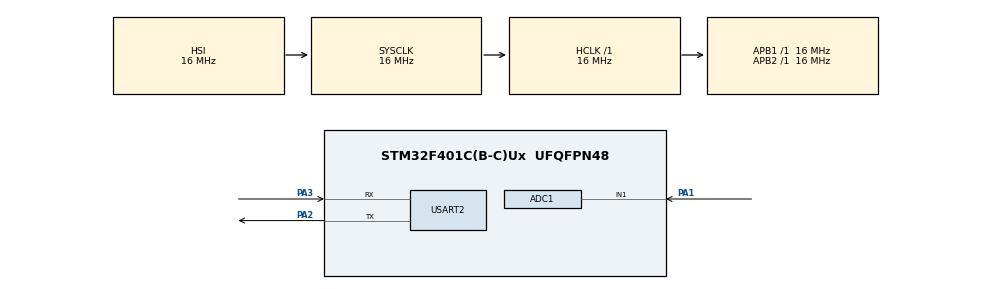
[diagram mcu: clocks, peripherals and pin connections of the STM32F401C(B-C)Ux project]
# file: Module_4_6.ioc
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ADC1.Channel-3\#ChannelRegularConversion=ADC_CHANNEL_1
ADC1.ContinuousConvMode=ENABLE
ADC1.NbrOfConversionFlag=1
ADC1.Rank-3\#ChannelRegularConversion=1
ADC1.SamplingTime-3\#ChannelRegularConversion=ADC_SAMPLETIME_3CYCLES
ADC1.master=1
Dma.ADC1.0.Direction=DMA_PERIPH_TO_MEMORY
Dma.ADC1.0.FIFOMode=DMA_FIFOMODE_DISABLE
Dma.ADC1.0.Instance=DMA2_Stream0
Dma.ADC1.0.MemDataAlignment=DMA_MDATAALIGN_HALFWORD
Dma.ADC1.0.MemInc=DMA_MINC_ENABLE
Dma.ADC1.0.Mode=DMA_CIRCULAR
Dma.ADC1.0.PeriphDataAlignment=DMA_PDATAALIGN_HALFWORD
Dma.ADC1.0.PeriphInc=DMA_PINC_DISABLE
Dma.ADC1.0.Priority=DMA_PRIORITY_LOW
Dma.Request0=ADC1
Dma.Request1=USART2_TX
Dma.USART2_TX.1.Direction=DMA_MEMORY_TO_PERIPH
Dma.USART2_TX.1.FIFOMode=DMA_FIFOMODE_DISABLE
Dma.USART2_TX.1.Instance=DMA1_Stream6
Dma.USART2_TX.1.MemDataAlignment=DMA_MDATAALIGN_BYTE
Dma.USART2_TX.1.MemInc=DMA_MINC_ENABLE
Dma.USART2_TX.1.Mode=DMA_NORMAL
Dma.USART2_TX.1.PeriphDataAlignment=DMA_PDATAALIGN_BYTE
Dma.USART2_TX.1.PeriphInc=DMA_PINC_DISABLE
Dma.USART2_TX.1.Priority=DMA_PRIORITY_LOW
Mcu.Family=STM32F4
Mcu.Name=STM32F401C(B-C)Ux
Mcu.Package=UFQFPN48
NVIC.DMA1_Stream6_IRQn=true\:0\:0\:false\:false\:true\:false\:true\:true
NVIC.DMA2_Stream0_IRQn=true\:0\:0\:false\:false\:true\:false\:true\:true
NVIC.PriorityGroup=NVIC_PRIORITYGROUP_4
NVIC.USART2_IRQn=true\:0\:0\:false\:false\:true\:false\:true\:true
PA1.Signal=ADCx_IN1
PA13.Mode=Serial_Wire
PA13.Signal=SYS_JTMS-SWDIO
PA14.Mode=Serial_Wire
PA14.Signal=SYS_JTCK-SWCLK
PA2.Mode=Asynchronous
PA2.Signal=USART2_TX
PA3.Mode=Asynchronous
PA3.Signal=USART2_RX
ProjectManager.HeapSize=0x200
ProjectManager.StackSize=0x400
ProjectManager.TargetToolchain=STM32CubeIDE
RCC.AHBFreq_Value=16000000
RCC.APB1Freq_Value=16000000
RCC.APB2Freq_Value=16000000
RCC.CortexFreq_Value=16000000
RCC.HSE_VALUE=25000000
RCC.HSI_VALUE=16000000
RCC.LSE_VALUE=32768
RCC.SYSCLKFreq_VALUE=16000000
RCC.VCOOutputFreq_Value=192000000
SH.ADCx_IN1.0=ADC1_IN1,IN1
USART2.VirtualMode=VM_ASYNC
board=custom

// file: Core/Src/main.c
/* USER CODE BEGIN Header */
/**
  ******************************************************************************
  * @file           : main.c
  * @brief          : Main program body
  ******************************************************************************
  * @attention
  *
  * Copyright (c) 2026 STMicroelectronics.
  * All rights reserved.
  *
  * This software is licensed under terms that can be found in the LICENSE file
  * in the root directory of this software component.
  * If no LICENSE file comes with this software, it is provided AS-IS.
  *
  ******************************************************************************
  */
/* USER CODE END Header */
#include "main.h"

/* USER CODE BEGIN Includes */
#include <stdint.h>
#include <string.h>

/* USER CODE END Includes */

ADC_HandleTypeDef hadc1;
DMA_HandleTypeDef hdma_adc1;

UART_HandleTypeDef huart2;
DMA_HandleTypeDef hdma_usart2_tx;

/* USER CODE BEGIN PV */
uint16_t adc_buffer[1000];
/* USER CODE END PV */

void SystemClock_Config(void);
static void MX_GPIO_Init(void);
static void MX_DMA_Init(void);
static void MX_ADC1_Init(void);
static void MX_USART2_UART_Init(void);

/* USER CODE BEGIN 0 */

uint16_t convert_to_mv(uint16_t adc_raw) {
  uint16_t signal_mv = (3300 * adc_raw)/4095 ;
  return signal_mv;
}

void  HAL_ADC_ConvCpltCallback( ADC_HandleTypeDef* hadc) {
   uint16_t min_adc_value=  0;
  uint16_t max_adc_value=  0;
  uint32_t avg_adc_value=  0;
  uint16_t pp_adc_value = 0;
    for (size_t i = 0; i < 1000; i++)
    {
      uint16_t current_value = adc_buffer[i];
      avg_adc_value+=current_value;
      if(i == 0) {
        min_adc_value = current_value;
        max_adc_value = current_value;
        continue;
      }
      if(min_adc_value > current_value) {
        min_adc_value = current_value;
      }
      if(max_adc_value < current_value) {
        max_adc_value = current_value;
      }
    }
    avg_adc_value = avg_adc_value / 1000;
    pp_adc_value = max_adc_value - min_adc_value;

      static char log[80];
      int len = snprintf(log, 80, "Vmax: %d mV; Vmin: %d mV; Vavg: %d mV; Vpp: %d mV\n", convert_to_mv(max_adc_value), convert_to_mv(min_adc_value), convert_to_mv(avg_adc_value), convert_to_mv(pp_adc_value));
      HAL_UART_Transmit_DMA(&huart2, log, len);

}

/* USER CODE END 0 */

int main(void)
{

  /* MCU Configuration--------------------------------------------------------*/

  /* Reset of all peripherals, Initializes the Flash interface and the Systick. */
  HAL_Init();

  /* Configure the system clock */
  SystemClock_Config();

  /* Initialize all configured peripherals */
  MX_GPIO_Init();
  MX_DMA_Init();
  MX_ADC1_Init();
  MX_USART2_UART_Init();
  /* USER CODE BEGIN 2 */
  HAL_ADC_Start_DMA(&hadc1, (uint32_t*)adc_buffer, 1000);
  /* USER CODE END 2 */

  /* Infinite loop */
  while (1)
  {

  }
}

void SystemClock_Config(void)
{
  RCC_OscInitTypeDef RCC_OscInitStruct = {0};
  RCC_ClkInitTypeDef RCC_ClkInitStruct = {0};

  /** Configure the main internal regulator output voltage
  */
  __HAL_RCC_PWR_CLK_ENABLE();
  __HAL_PWR_VOLTAGESCALING_CONFIG(PWR_REGULATOR_VOLTAGE_SCALE2);

  /** Initializes the RCC Oscillators according to the specified parameters
  * in the RCC_OscInitTypeDef structure.
  */
  RCC_OscInitStruct.OscillatorType = RCC_OSCILLATORTYPE_HSI;
  RCC_OscInitStruct.HSIState = RCC_HSI_ON;
  RCC_OscInitStruct.HSICalibrationValue = RCC_HSICALIBRATION_DEFAULT;
  RCC_OscInitStruct.PLL.PLLState = RCC_PLL_NONE;
  if (HAL_RCC_OscConfig(&RCC_OscInitStruct) != HAL_OK)
  {
    Error_Handler();
  }

  /** Initializes the CPU, AHB and APB buses clocks
  */
  RCC_ClkInitStruct.ClockType = RCC_CLOCKTYPE_HCLK|RCC_CLOCKTYPE_SYSCLK
                              |RCC_CLOCKTYPE_PCLK1|RCC_CLOCKTYPE_PCLK2;
  RCC_ClkInitStruct.SYSCLKSource = RCC_SYSCLKSOURCE_HSI;
  RCC_ClkInitStruct.AHBCLKDivider = RCC_SYSCLK_DIV1;
  RCC_ClkInitStruct.APB1CLKDivider = RCC_HCLK_DIV1;
  RCC_ClkInitStruct.APB2CLKDivider = RCC_HCLK_DIV1;

  if (HAL_RCC_ClockConfig(&RCC_ClkInitStruct, FLASH_LATENCY_0) != HAL_OK)
  {
    Error_Handler();
  }
}

static void MX_ADC1_Init(void)
{

  ADC_ChannelConfTypeDef sConfig = {0};

  /** Configure the global features of the ADC (Clock, Resolution, Data Alignment and number of conversion)
  */
  hadc1.Instance = ADC1;
  hadc1.Init.ClockPrescaler = ADC_CLOCK_SYNC_PCLK_DIV2;
  hadc1.Init.Resolution = ADC_RESOLUTION_12B;
  hadc1.Init.ScanConvMode = DISABLE;
  hadc1.Init.ContinuousConvMode = ENABLE;
  hadc1.Init.DiscontinuousConvMode = DISABLE;
  hadc1.Init.ExternalTrigConvEdge = ADC_EXTERNALTRIGCONVEDGE_NONE;
  hadc1.Init.ExternalTrigConv = ADC_SOFTWARE_START;
  hadc1.Init.DataAlign = ADC_DATAALIGN_RIGHT;
  hadc1.Init.NbrOfConversion = 1;
  hadc1.Init.DMAContinuousRequests = DISABLE;
  hadc1.Init.EOCSelection = ADC_EOC_SINGLE_CONV;
  if (HAL_ADC_Init(&hadc1) != HAL_OK)
  {
    Error_Handler();
  }

  /** Configure for the selected ADC regular channel its corresponding rank in the sequencer and its sample time.
  */
  sConfig.Channel = ADC_CHANNEL_1;
  sConfig.Rank = 1;
  sConfig.SamplingTime = ADC_SAMPLETIME_3CYCLES;
  if (HAL_ADC_ConfigChannel(&hadc1, &sConfig) != HAL_OK)
  {
    Error_Handler();
  }

}

static void MX_USART2_UART_Init(void)
{

  huart2.Instance = USART2;
  huart2.Init.BaudRate = 115200;
  huart2.Init.WordLength = UART_WORDLENGTH_8B;
  huart2.Init.StopBits = UART_STOPBITS_1;
  huart2.Init.Parity = UART_PARITY_NONE;
  huart2.Init.Mode = UART_MODE_TX_RX;
  huart2.Init.HwFlowCtl = UART_HWCONTROL_NONE;
  huart2.Init.OverSampling = UART_OVERSAMPLING_16;
  if (HAL_UART_Init(&huart2) != HAL_OK)
  {
    Error_Handler();
  }

}

static void MX_DMA_Init(void)
{

  /* DMA controller clock enable */
  __HAL_RCC_DMA2_CLK_ENABLE();
  __HAL_RCC_DMA1_CLK_ENABLE();

  /* DMA interrupt init */
  /* DMA1_Stream6_IRQn interrupt configuration */
  HAL_NVIC_SetPriority(DMA1_Stream6_IRQn, 0, 0);
  HAL_NVIC_EnableIRQ(DMA1_Stream6_IRQn);
  /* DMA2_Stream0_IRQn interrupt configuration */
  HAL_NVIC_SetPriority(DMA2_Stream0_IRQn, 0, 0);
  HAL_NVIC_EnableIRQ(DMA2_Stream0_IRQn);

}

static void MX_GPIO_Init(void)
{

  /* GPIO Ports Clock Enable */
  __HAL_RCC_GPIOA_CLK_ENABLE();

}

void Error_Handler(void)
{
  __disable_irq();
  while (1)
  {
  }
}
